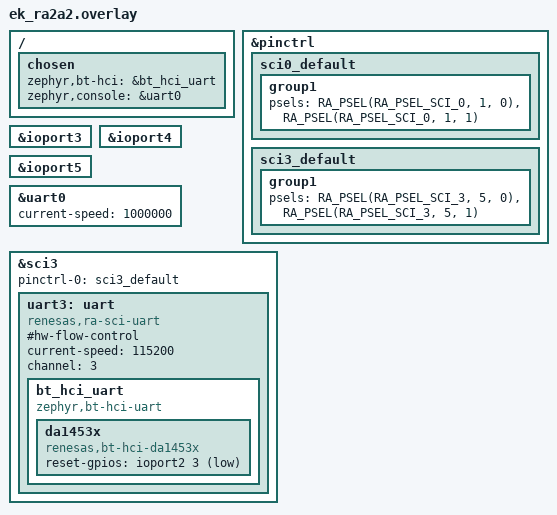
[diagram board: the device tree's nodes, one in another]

&pinctrl {
	sci0_default: sci0_default {
		group1 {
			/* tx rx */
			psels = <RA_PSEL(RA_PSEL_SCI_0, 1, 0)>,
			<RA_PSEL(RA_PSEL_SCI_0, 1, 1)>;
		};
	};
	sci3_default: sci3_default {
		group1 {
			/* tx rx */
			psels = <RA_PSEL(RA_PSEL_SCI_3, 5, 0)>,
			<RA_PSEL(RA_PSEL_SCI_3, 5, 1)>;
		};
	};
};

/ {
	chosen {
		zephyr,bt-hci = &bt_hci_uart;
		zephyr,console = &uart0;
	};
};


&ioport3 {
    status = "okay";
};
&ioport4 {
    status = "okay";
};
&ioport5 {
    status = "okay";
};

&uart0{
	current-speed = <1000000>;
};

&sci3 {
    pinctrl-0 = <&sci3_default>;
    pinctrl-names = "default";
    status = "okay";
    uart3: uart {
		compatible = "renesas,ra-sci-uart";
        #hw-flow-control;
        current-speed = <115200>;
        status = "okay";
		channel = <3>;

        bt_hci_uart: bt_hci_uart {
            compatible = "zephyr,bt-hci-uart";
            status = "okay";

            da1453x {
                compatible = "renesas,bt-hci-da1453x";
                reset-gpios = <&ioport2 3 GPIO_ACTIVE_LOW>;
                status = "okay";
            };
        };
    };
};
